VERSION "0.1-draft"

NS_ :

BS_:

BU_: ECU1_VCU ECU2_Pedal ECU3_Body JETSON_GW

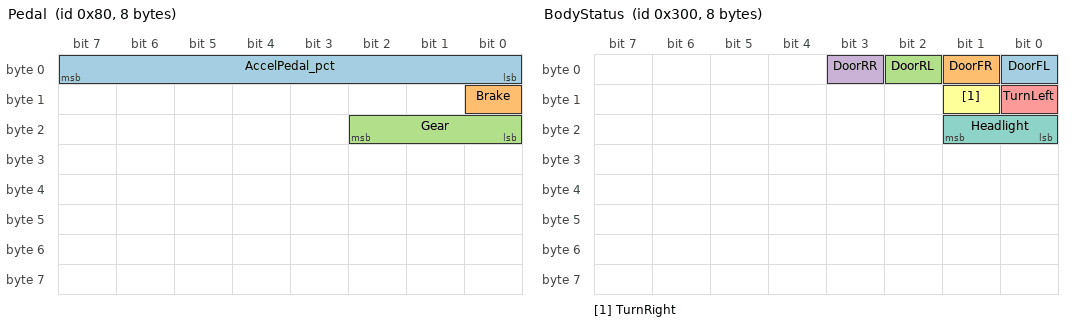
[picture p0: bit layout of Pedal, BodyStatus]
BO_ 128 Pedal: 8 ECU2_Pedal
 SG_ AccelPedal_pct : 0|8@1+ (0.5,0) [0|100] "%" ECU1_VCU,JETSON_GW
 SG_ Brake : 8|1@1+ (1,0) [0|1] "" ECU1_VCU,ECU3_Body,JETSON_GW
 SG_ Gear : 16|3@1+ (1,0) [0|7] "" ECU1_VCU,JETSON_GW

BO_ 256 VehSpeed: 8 ECU1_VCU
 SG_ VehicleSpeed : 0|16@1+ (0.01,0) [0|250] "km/h" JETSON_GW
 SG_ MotorRpm : 16|16@1- (1,0) [-12000|12000] "rpm" JETSON_GW

BO_ 768 BodyStatus: 8 ECU3_Body
 SG_ DoorFL : 0|1@1+ (1,0) [0|1] "" ECU1_VCU,JETSON_GW
 SG_ DoorFR : 1|1@1+ (1,0) [0|1] "" ECU1_VCU,JETSON_GW
 SG_ DoorRL : 2|1@1+ (1,0) [0|1] "" ECU1_VCU,JETSON_GW
 SG_ DoorRR : 3|1@1+ (1,0) [0|1] "" ECU1_VCU,JETSON_GW
 SG_ TurnLeft : 8|1@1+ (1,0) [0|1] "" JETSON_GW
 SG_ TurnRight : 9|1@1+ (1,0) [0|1] "" JETSON_GW
 SG_ Headlight : 16|2@1+ (1,0) [0|3] "" JETSON_GW

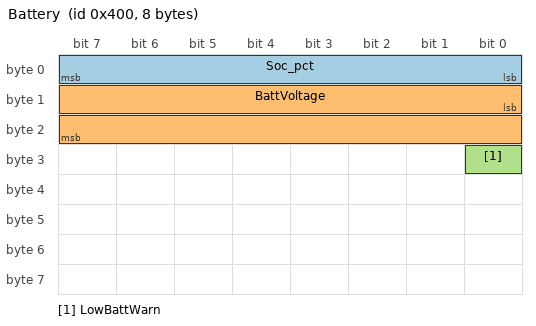
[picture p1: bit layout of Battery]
BO_ 1024 Battery: 8 ECU1_VCU
 SG_ Soc_pct : 0|8@1+ (0.5,0) [0|100] "%" JETSON_GW
 SG_ BattVoltage : 8|16@1+ (0.1,0) [0|500] "V" JETSON_GW
 SG_ LowBattWarn : 24|1@1+ (1,0) [0|1] "" JETSON_GW

CM_ "Mang CAN mo phong o to tren ban (DAKS). Ban nhap 0.1, se chinh. CAN thuong 500 kbit/s, ID 11 bit. Quy uoc chung: moi message dai 8 byte (du cho de them tin hieu ma khong doi DLC); byte order Intel (little endian); gia tri tho toan bit 1 = SNA (khong co du lieu). Dai ID: 0x080-0x1FF truyen dong + khung gam, 0x300-0x3FF than xe, 0x400-0x4FF pin, 0x500-0x5FF HMI gui nguoc, 0x700-0x7FF chan doan UDS.";
CM_ BU_ ECU1_VCU "VCU: board Hiwonder ROS Robot Controller (STM32F407VET6) chay Trampoline OSEK. Chua mo hinh xe don gian, dat o mot dau bus (tro 120 ohm R23 co san tren board).";
CM_ BU_ ECU2_Pedal "Pedal: STM32F103C8T6 + SN65HVD230. Bien tro = chan ga, nut = phanh, cong tac = so P/R/N/D.";
CM_ BU_ ECU3_Body "Body: STM32F103C8T6 + SN65HVD230. Cong tac cua, can xi-nhan, den pha; dieu khien LED xi-nhan va LED phanh.";
CM_ BU_ JETSON_GW "Jetson Orin Nano: gateway/cockpit. Chi nghe bus (chua gui gi), giai ma theo DBC nay roi gui sang Android theo TEN tin hieu.";
CM_ BO_ 128 "Trang thai ban dap va can so. Gui moi 20 ms. Byte 6-7 de trong, du phong cho E2E (counter + CRC) neu chon phan mo rong E2E.";
CM_ SG_ 128 AccelPedal_pct "Do dap chan ga. Buoc 0.5 % (201 muc cho 0-100 %, du min so voi bien tro qua ADC 12 bit). Tho 255 = SNA, vi du dut day bien tro.";
CM_ SG_ 128 Brake "Nut phanh: 1 = dang dap. ECU3 dung tin hieu nay de bat LED phanh.";
CM_ SG_ 128 Gear "Vi tri can so. 3 bit, du cho 4 so + du phong; 7 = SNA.";
CM_ BO_ 256 "Trang thai chuyen dong tu mo hinh xe trong VCU. Gui moi 20 ms.";
CM_ SG_ 256 VehicleSpeed "Toc do xe (do lon, khong dau). Buoc 0.01 km/h, 16 bit toi 655.34 km/h; mo hinh gioi han 250. Chieu chay suy tu Gear. Tho 0xFFFF = SNA.";
CM_ SG_ 256 MotorRpm "Vong quay mo-to, CO DAU: am khi lui (so R). 16 bit co dau, buoc 1 rpm. Gia su mo-to toi da 12000 rpm (co the chinh theo mo hinh). Tho 0x8000 = SNA.";
CM_ BO_ 768 "Trang thai than xe. Gui moi 100 ms VA gui ngay khi co tin hieu doi (khong nhanh hon GenMsgDelayTime).";
CM_ SG_ 768 DoorFL "Cua truoc trai: 1 = mo. Ban cung dau tien chi co 1 cong tac cua noi vao DoorFL; 3 cua con lai gui 0 (dong).";
CM_ SG_ 768 TurnLeft "Can xi-nhan gat sang trai (1 = dang bat). Day la trang thai CAN GAT, khong phai trang thai den dang sang: ECU3 tu nhay LED, HMI tu nhay bieu tuong.";
CM_ SG_ 768 TurnRight "Can xi-nhan gat sang phai (1 = dang bat). Xem ghi chu TurnLeft.";
CM_ SG_ 768 Headlight "Den pha. 2 bit: 0 tat, 1 cos, 2 pha, 3 SNA. Ban cung dau chi co cong tac bat/tat (0/1); muc 2 de danh.";
CM_ BO_ 1024 "Trang thai pin tu mo hinh trong VCU. Gui moi 500 ms (pin thay doi cham).";
CM_ SG_ 1024 Soc_pct "Muc pin con lai. Buoc 0.5 %. Tho 255 = SNA.";
CM_ SG_ 1024 BattVoltage "Dien ap bo pin mo phong. Buoc 0.1 V, 16 bit. Gia su bo pin xe dien khoang 350-400 V (so mo phong, khong phai pin that). Tho 0xFFFF = SNA.";
CM_ SG_ 1024 LowBattWarn "Canh bao pin yeu: 1 = Soc duoi nguong (nguong dat trong VCU, du kien 20 %).";

BA_DEF_ "BusType" STRING ;
BA_DEF_ "Baudrate" INT 0 1000000;
BA_DEF_ BO_ "GenMsgCycleTime" INT 0 65535;
BA_DEF_ BO_ "GenMsgSendType" ENUM "Cyclic","CyclicAndOnChange";
BA_DEF_ BO_ "GenMsgDelayTime" INT 0 65535;
BA_DEF_ BO_ "GenMsgTimeoutTime" INT 0 65535;
BA_DEF_DEF_ "BusType" "CAN";
BA_DEF_DEF_ "Baudrate" 500000;
BA_DEF_DEF_ "GenMsgCycleTime" 0;
BA_DEF_DEF_ "GenMsgSendType" "Cyclic";
BA_DEF_DEF_ "GenMsgDelayTime" 0;
BA_DEF_DEF_ "GenMsgTimeoutTime" 0;
BA_ "GenMsgCycleTime" BO_ 128 20;
BA_ "GenMsgTimeoutTime" BO_ 128 100;
BA_ "GenMsgCycleTime" BO_ 256 20;
BA_ "GenMsgTimeoutTime" BO_ 256 100;
BA_ "GenMsgCycleTime" BO_ 768 100;
BA_ "GenMsgSendType" BO_ 768 1;
BA_ "GenMsgDelayTime" BO_ 768 20;
BA_ "GenMsgTimeoutTime" BO_ 768 500;
BA_ "GenMsgCycleTime" BO_ 1024 500;
BA_ "GenMsgTimeoutTime" BO_ 1024 2500;

VAL_ 128 AccelPedal_pct 255 "SNA" ;
VAL_ 128 Gear 7 "SNA" 3 "D" 2 "N" 1 "R" 0 "P" ;
VAL_ 256 VehicleSpeed 65535 "SNA" ;
VAL_ 256 MotorRpm -32768 "SNA" ;
VAL_ 768 Headlight 3 "SNA" 2 "HighBeam" 1 "LowBeam" 0 "Off" ;
VAL_ 1024 Soc_pct 255 "SNA" ;
VAL_ 1024 BattVoltage 65535 "SNA" ;

SIG_GROUP_ 128 PedalGroup 1 : AccelPedal_pct Brake Gear;
